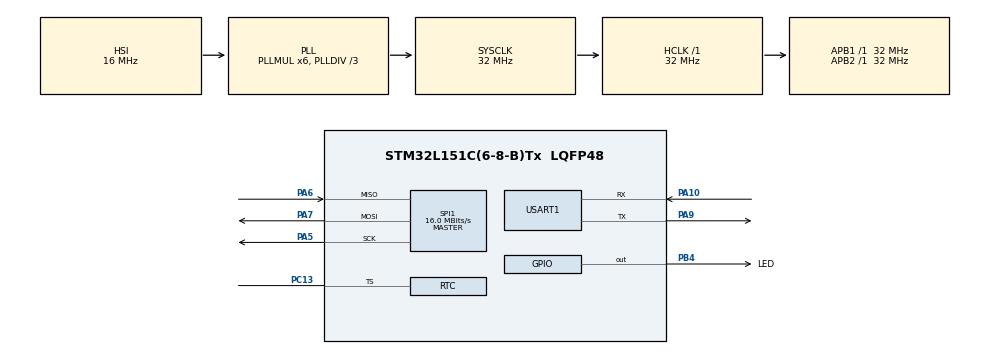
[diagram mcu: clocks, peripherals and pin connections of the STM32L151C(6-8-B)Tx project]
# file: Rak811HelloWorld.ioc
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ADC.Channel-0\#ChannelRegularConversion=ADC_CHANNEL_TEMPSENSOR
ADC.NbrOfConversionFlag=1
ADC.Rank-0\#ChannelRegularConversion=1
ADC.SamplingTime-0\#ChannelRegularConversion=ADC_SAMPLETIME_4CYCLES
Mcu.Family=STM32L1
Mcu.Name=STM32L151C(6-8-B)Tx
Mcu.Package=LQFP48
NVIC.PriorityGroup=NVIC_PRIORITYGROUP_4
PA10.Mode=Asynchronous
PA10.Signal=USART1_RX
PA13.Mode=Serial_Wire
PA13.Signal=SYS_JTMS-SWDIO
PA14.Mode=Serial_Wire
PA14.Signal=SYS_JTCK-SWCLK
PA5.Mode=Full_Duplex_Master
PA5.Signal=SPI1_SCK
PA6.Mode=Full_Duplex_Master
PA6.Signal=SPI1_MISO
PA7.Mode=Full_Duplex_Master
PA7.Signal=SPI1_MOSI
PA9.Mode=Asynchronous
PA9.Signal=USART1_TX
PB4.GPIO_Label=LED
PB4.GPIO_Speed=GPIO_SPEED_FREQ_HIGH
PB4.PinState=GPIO_PIN_SET
PB4.Signal=GPIO_Output
PB7.Mode=Mode_PVD_Ext
PB7.Signal=SYS_PVD_IN
PC13-WKUP2.Mode=Timestamp enabled - Input Enabled to TS
PC13-WKUP2.Signal=RTC_TS
PC14-OSC32_IN.Mode=LSE-External-Oscillator
PC14-OSC32_IN.Signal=RCC_OSC32_IN
PC15-OSC32_OUT.Mode=LSE-External-Oscillator
PC15-OSC32_OUT.Signal=RCC_OSC32_OUT
ProjectManager.HeapSize=0x200
ProjectManager.StackSize=0x400
ProjectManager.TargetToolchain=SW4STM32
RCC.48MHZClocksFreq_Value=48000000
RCC.AHBFreq_Value=32000000
RCC.APB1Freq_Value=32000000
RCC.APB1TimFreq_Value=32000000
RCC.APB2Freq_Value=32000000
RCC.APB2TimFreq_Value=32000000
RCC.HCLKFreq_Value=32000000
RCC.HSE_VALUE=24000000
RCC.HSI_VALUE=16000000
RCC.MSI_VALUE=2097000
RCC.PLLDIV=RCC_PLL_DIV3
RCC.PLLMUL=RCC_PLL_MUL6
RCC.RCC_MCOSource=RCC_MCO1SOURCE_HSE
RCC.SYSCLKFreq_VALUE=32000000
RCC.SYSCLKSource=RCC_SYSCLKSOURCE_PLLCLK
RCC.VCOOutputFreq_Value=96000000
SPI1.CalculateBaudRate=16.0 MBits/s
SPI1.Direction=SPI_DIRECTION_2LINES
SPI1.Mode=SPI_MODE_MASTER
SPI1.VirtualType=VM_MASTER
USART1.VirtualMode=VM_ASYNC
VP_ADC_TempSens_Input.Mode=IN-TempSens
VP_RTC_VS_RTC_Activate.Mode=RTC_Enabled
VP_RTC_VS_RTC_Calendar.Mode=RTC_Calendar
board=custom

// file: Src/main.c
/**
  ******************************************************************************
  * @file           : main.c
  * @brief          : Main program body
  ******************************************************************************
  ** This notice applies to any and all portions of this file
  * that are not between comment pairs USER CODE BEGIN and
  * USER CODE END. Other portions of this file, whether
  * inserted by the user or by software development tools
  * are owned by their respective copyright owners.
  *
  * COPYRIGHT(c) 2018 STMicroelectronics
  *
  * Redistribution and use in source and binary forms, with or without modification,
  * are permitted provided that the following conditions are met:
  *   1. Redistributions of source code must retain the above copyright notice,
  *      this list of conditions and the following disclaimer.
  *   2. Redistributions in binary form must reproduce the above copyright notice,
  *      this list of conditions and the following disclaimer in the documentation
  *      and/or other materials provided with the distribution.
  *   3. Neither the name of STMicroelectronics nor the names of its contributors
  *      may be used to endorse or promote products derived from this software
  *      without specific prior written permission.
  *
  * THIS SOFTWARE IS PROVIDED BY THE COPYRIGHT HOLDERS AND CONTRIBUTORS "AS IS"
  * AND ANY EXPRESS OR IMPLIED WARRANTIES, INCLUDING, BUT NOT LIMITED TO, THE
  * IMPLIED WARRANTIES OF MERCHANTABILITY AND FITNESS FOR A PARTICULAR PURPOSE ARE
  * DISCLAIMED. IN NO EVENT SHALL THE COPYRIGHT HOLDER OR CONTRIBUTORS BE LIABLE
  * FOR ANY DIRECT, INDIRECT, INCIDENTAL, SPECIAL, EXEMPLARY, OR CONSEQUENTIAL
  * DAMAGES (INCLUDING, BUT NOT LIMITED TO, PROCUREMENT OF SUBSTITUTE GOODS OR
  * SERVICES; LOSS OF USE, DATA, OR PROFITS; OR BUSINESS INTERRUPTION) HOWEVER
  * CAUSED AND ON ANY THEORY OF LIABILITY, WHETHER IN CONTRACT, STRICT LIABILITY,
  * OR TORT (INCLUDING NEGLIGENCE OR OTHERWISE) ARISING IN ANY WAY OUT OF THE USE
  * OF THIS SOFTWARE, EVEN IF ADVISED OF THE POSSIBILITY OF SUCH DAMAGE.
  *
  ******************************************************************************
  */
#include "main.h"
#include "stm32l1xx_hal.h"

/* USER CODE BEGIN Includes */
#include <string.h>

/* USER CODE END Includes */

ADC_HandleTypeDef hadc;

RTC_HandleTypeDef hrtc;

SPI_HandleTypeDef hspi1;

UART_HandleTypeDef huart1;

/* USER CODE BEGIN PV */
/* Private variables ---------------------------------------------------------*/

/* USER CODE END PV */

void SystemClock_Config(void);
static void MX_GPIO_Init(void);
static void MX_ADC_Init(void);
static void MX_SPI1_Init(void);
static void MX_RTC_Init(void);
static void MX_USART1_UART_Init(void);

/* USER CODE BEGIN PFP */
/* Private function prototypes -----------------------------------------------*/

/* USER CODE END PFP */

int main(void)
{
  /* USER CODE BEGIN 1 */
//	char *helloWorldOff = "Hello World! The LED is off\r\n";
//	char *helloWorldOn = "Hello World! The LED is on\r\n";

  /* USER CODE END 1 */

  /* MCU Configuration----------------------------------------------------------*/

  /* Reset of all peripherals, Initializes the Flash interface and the Systick. */
  HAL_Init();

  /* Configure the system clock */
  SystemClock_Config();

  /* Initialize all configured peripherals */
  MX_GPIO_Init();
  MX_ADC_Init();
  MX_SPI1_Init();
  MX_RTC_Init();
  MX_USART1_UART_Init();
  /* USER CODE BEGIN 2 */

  register int sp asm ("sp");
  printf("\r\nstack pointer %x\r\n", sp);

  /* USER CODE END 2 */

  /* Infinite loop */
  /* USER CODE BEGIN WHILE */
  while (1)
  {
	  HAL_Delay(1000);
	  HAL_GPIO_WritePin(LED_GPIO_Port, LED_Pin,GPIO_PIN_SET);
	  printf("Hello World! The LED is off\r\n");
//	  HAL_UART_Transmit(&huart1, (uint8_t *)helloWorldOn, (uint16_t)strlen(helloWorldOn),100);

	  HAL_Delay(1000);
	  HAL_GPIO_WritePin(LED_GPIO_Port, LED_Pin,GPIO_PIN_RESET);
	  printf("Hello World! The LED is on\r\n");
//	  HAL_UART_Transmit(&huart1, (uint8_t *)helloWorldOff, (uint16_t)strlen(helloWorldOff),100);

  /* USER CODE END WHILE */

  }

}

void SystemClock_Config(void)
{

  RCC_OscInitTypeDef RCC_OscInitStruct;
  RCC_ClkInitTypeDef RCC_ClkInitStruct;
  RCC_PeriphCLKInitTypeDef PeriphClkInit;

    /**Configure the main internal regulator output voltage
    */
  __HAL_PWR_VOLTAGESCALING_CONFIG(PWR_REGULATOR_VOLTAGE_SCALE1);

    /**Initializes the CPU, AHB and APB busses clocks
    */
  RCC_OscInitStruct.OscillatorType = RCC_OSCILLATORTYPE_HSI|RCC_OSCILLATORTYPE_LSI;
  RCC_OscInitStruct.HSIState = RCC_HSI_ON;
  RCC_OscInitStruct.HSICalibrationValue = 16;
  RCC_OscInitStruct.LSIState = RCC_LSI_ON;
  RCC_OscInitStruct.PLL.PLLState = RCC_PLL_ON;
  RCC_OscInitStruct.PLL.PLLSource = RCC_PLLSOURCE_HSI;
  RCC_OscInitStruct.PLL.PLLMUL = RCC_PLL_MUL6;
  RCC_OscInitStruct.PLL.PLLDIV = RCC_PLL_DIV3;
  if (HAL_RCC_OscConfig(&RCC_OscInitStruct) != HAL_OK)
  {
    _Error_Handler(__FILE__, __LINE__);
  }

    /**Initializes the CPU, AHB and APB busses clocks
    */
  RCC_ClkInitStruct.ClockType = RCC_CLOCKTYPE_HCLK|RCC_CLOCKTYPE_SYSCLK
                              |RCC_CLOCKTYPE_PCLK1|RCC_CLOCKTYPE_PCLK2;
  RCC_ClkInitStruct.SYSCLKSource = RCC_SYSCLKSOURCE_PLLCLK;
  RCC_ClkInitStruct.AHBCLKDivider = RCC_SYSCLK_DIV1;
  RCC_ClkInitStruct.APB1CLKDivider = RCC_HCLK_DIV1;
  RCC_ClkInitStruct.APB2CLKDivider = RCC_HCLK_DIV1;

  if (HAL_RCC_ClockConfig(&RCC_ClkInitStruct, FLASH_LATENCY_1) != HAL_OK)
  {
    _Error_Handler(__FILE__, __LINE__);
  }

  PeriphClkInit.PeriphClockSelection = RCC_PERIPHCLK_RTC;
  PeriphClkInit.RTCClockSelection = RCC_RTCCLKSOURCE_LSI;
  if (HAL_RCCEx_PeriphCLKConfig(&PeriphClkInit) != HAL_OK)
  {
    _Error_Handler(__FILE__, __LINE__);
  }

    /**Configure the Systick interrupt time
    */
  HAL_SYSTICK_Config(HAL_RCC_GetHCLKFreq()/1000);

    /**Configure the Systick
    */
  HAL_SYSTICK_CLKSourceConfig(SYSTICK_CLKSOURCE_HCLK);

  /* SysTick_IRQn interrupt configuration */
  HAL_NVIC_SetPriority(SysTick_IRQn, 0, 0);
}

/* ADC init function */
static void MX_ADC_Init(void)
{

  ADC_ChannelConfTypeDef sConfig;

    /**Configure the global features of the ADC (Clock, Resolution, Data Alignment and number of conversion)
    */
  hadc.Instance = ADC1;
  hadc.Init.ClockPrescaler = ADC_CLOCK_ASYNC_DIV1;
  hadc.Init.Resolution = ADC_RESOLUTION_12B;
  hadc.Init.DataAlign = ADC_DATAALIGN_RIGHT;
  hadc.Init.ScanConvMode = ADC_SCAN_DISABLE;
  hadc.Init.EOCSelection = ADC_EOC_SEQ_CONV;
  hadc.Init.LowPowerAutoWait = ADC_AUTOWAIT_DISABLE;
  hadc.Init.LowPowerAutoPowerOff = ADC_AUTOPOWEROFF_DISABLE;
  hadc.Init.ChannelsBank = ADC_CHANNELS_BANK_A;
  hadc.Init.ContinuousConvMode = DISABLE;
  hadc.Init.NbrOfConversion = 1;
  hadc.Init.DiscontinuousConvMode = DISABLE;
  hadc.Init.ExternalTrigConv = ADC_SOFTWARE_START;
  hadc.Init.ExternalTrigConvEdge = ADC_EXTERNALTRIGCONVEDGE_NONE;
  hadc.Init.DMAContinuousRequests = DISABLE;
  if (HAL_ADC_Init(&hadc) != HAL_OK)
  {
    _Error_Handler(__FILE__, __LINE__);
  }

    /**Configure for the selected ADC regular channel its corresponding rank in the sequencer and its sample time.
    */
  sConfig.Channel = ADC_CHANNEL_TEMPSENSOR;
  sConfig.Rank = ADC_REGULAR_RANK_1;
  sConfig.SamplingTime = ADC_SAMPLETIME_4CYCLES;
  if (HAL_ADC_ConfigChannel(&hadc, &sConfig) != HAL_OK)
  {
    _Error_Handler(__FILE__, __LINE__);
  }

}

/* RTC init function */
static void MX_RTC_Init(void)
{

  RTC_TimeTypeDef sTime;
  RTC_DateTypeDef sDate;

    /**Initialize RTC Only
    */
  hrtc.Instance = RTC;
  hrtc.Init.HourFormat = RTC_HOURFORMAT_24;
  hrtc.Init.AsynchPrediv = 127;
  hrtc.Init.SynchPrediv = 255;
  hrtc.Init.OutPut = RTC_OUTPUT_DISABLE;
  hrtc.Init.OutPutPolarity = RTC_OUTPUT_POLARITY_HIGH;
  hrtc.Init.OutPutType = RTC_OUTPUT_TYPE_OPENDRAIN;
  if (HAL_RTC_Init(&hrtc) != HAL_OK)
  {
    _Error_Handler(__FILE__, __LINE__);
  }

    /**Initialize RTC and set the Time and Date
    */
  sTime.Hours = 0x0;
  sTime.Minutes = 0x0;
  sTime.Seconds = 0x0;
  sTime.DayLightSaving = RTC_DAYLIGHTSAVING_NONE;
  sTime.StoreOperation = RTC_STOREOPERATION_RESET;
  if (HAL_RTC_SetTime(&hrtc, &sTime, RTC_FORMAT_BCD) != HAL_OK)
  {
    _Error_Handler(__FILE__, __LINE__);
  }

  sDate.WeekDay = RTC_WEEKDAY_MONDAY;
  sDate.Month = RTC_MONTH_JANUARY;
  sDate.Date = 0x1;
  sDate.Year = 0x0;

  if (HAL_RTC_SetDate(&hrtc, &sDate, RTC_FORMAT_BCD) != HAL_OK)
  {
    _Error_Handler(__FILE__, __LINE__);
  }

    /**Enable the TimeStamp
    */
  if (HAL_RTCEx_SetTimeStamp(&hrtc, RTC_TIMESTAMPEDGE_RISING) != HAL_OK)
  {
    _Error_Handler(__FILE__, __LINE__);
  }

}

/* SPI1 init function */
static void MX_SPI1_Init(void)
{

  /* SPI1 parameter configuration*/
  hspi1.Instance = SPI1;
  hspi1.Init.Mode = SPI_MODE_MASTER;
  hspi1.Init.Direction = SPI_DIRECTION_2LINES;
  hspi1.Init.DataSize = SPI_DATASIZE_8BIT;
  hspi1.Init.CLKPolarity = SPI_POLARITY_LOW;
  hspi1.Init.CLKPhase = SPI_PHASE_1EDGE;
  hspi1.Init.NSS = SPI_NSS_SOFT;
  hspi1.Init.BaudRatePrescaler = SPI_BAUDRATEPRESCALER_2;
  hspi1.Init.FirstBit = SPI_FIRSTBIT_MSB;
  hspi1.Init.TIMode = SPI_TIMODE_DISABLE;
  hspi1.Init.CRCCalculation = SPI_CRCCALCULATION_DISABLE;
  hspi1.Init.CRCPolynomial = 10;
  if (HAL_SPI_Init(&hspi1) != HAL_OK)
  {
    _Error_Handler(__FILE__, __LINE__);
  }

}

/* USART1 init function */
static void MX_USART1_UART_Init(void)
{

  huart1.Instance = USART1;
  huart1.Init.BaudRate = 115200;
  huart1.Init.WordLength = UART_WORDLENGTH_8B;
  huart1.Init.StopBits = UART_STOPBITS_1;
  huart1.Init.Parity = UART_PARITY_NONE;
  huart1.Init.Mode = UART_MODE_TX_RX;
  huart1.Init.HwFlowCtl = UART_HWCONTROL_NONE;
  huart1.Init.OverSampling = UART_OVERSAMPLING_16;
  if (HAL_UART_Init(&huart1) != HAL_OK)
  {
    _Error_Handler(__FILE__, __LINE__);
  }

}

/** Configure pins as
        * Analog
        * Input
        * Output
        * EVENT_OUT
        * EXTI
     PB7   ------> SYS_PVD_IN
*/
static void MX_GPIO_Init(void)
{

  GPIO_InitTypeDef GPIO_InitStruct;

  /* GPIO Ports Clock Enable */
  __HAL_RCC_GPIOC_CLK_ENABLE();
  __HAL_RCC_GPIOA_CLK_ENABLE();
  __HAL_RCC_GPIOB_CLK_ENABLE();

  /*Configure GPIO pin Output Level */
  HAL_GPIO_WritePin(LED_GPIO_Port, LED_Pin, GPIO_PIN_SET);

  /*Configure GPIO pin : LED_Pin */
  GPIO_InitStruct.Pin = LED_Pin;
  GPIO_InitStruct.Mode = GPIO_MODE_OUTPUT_PP;
  GPIO_InitStruct.Pull = GPIO_NOPULL;
  GPIO_InitStruct.Speed = GPIO_SPEED_FREQ_HIGH;
  HAL_GPIO_Init(LED_GPIO_Port, &GPIO_InitStruct);

  /*Configure GPIO pin : PB7 */
  GPIO_InitStruct.Pin = GPIO_PIN_7;
  GPIO_InitStruct.Mode = GPIO_MODE_ANALOG;
  GPIO_InitStruct.Pull = GPIO_NOPULL;
  HAL_GPIO_Init(GPIOB, &GPIO_InitStruct);

}

void _Error_Handler(char *file, int line)
{
  while(1)
  {
  }
}

/************************ (C) COPYRIGHT STMicroelectronics *****END OF FILE****/
